VERSION ""

NS_ :

BS_:

BU_: XXX

BO_ 640 NEW_MSG_1: 8 XXX
 SG_ NEW_SIGNAL_1 : 31|8@0+ (1,0) [0|255] "" XXX

BO_ 339 NEW_MSG_2: 8 XXX
 SG_ VEHICLE_SPEED : 23|8@0+ (1,0) [0|255] "" XXX

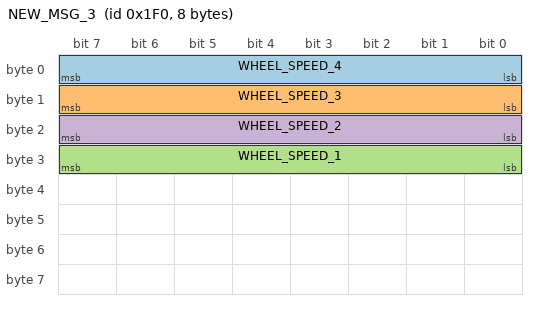
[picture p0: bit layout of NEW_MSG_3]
BO_ 496 NEW_MSG_3: 8 XXX
 SG_ WHEEL_SPEED_4 : 7|8@0+ (1,0) [0|255] "" XXX
 SG_ WHEEL_SPEED_3 : 15|8@0+ (1,0) [0|255] "" XXX
 SG_ WHEEL_SPEED_1 : 31|8@0+ (1,0) [0|255] "" XXX
 SG_ WHEEL_SPEED_2 : 23|8@0+ (1,0) [0|255] "" XXX
